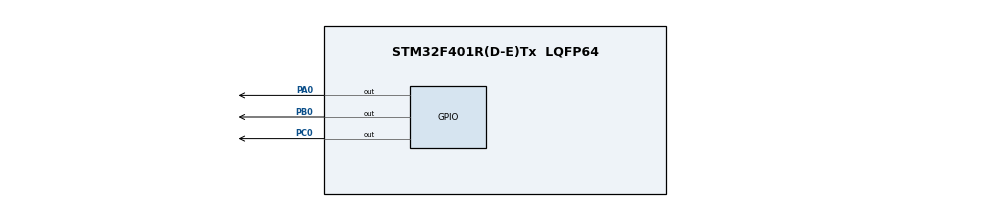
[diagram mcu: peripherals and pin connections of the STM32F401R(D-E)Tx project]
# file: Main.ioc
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Mcu.Family=STM32F4
Mcu.Name=STM32F401R(D-E)Tx
Mcu.Package=LQFP64
NVIC.PriorityGroup=NVIC_PRIORITYGROUP_4
PA0-WKUP.Signal=GPIO_Output
PA13.Mode=JTAG_4_pins
PA13.Signal=SYS_JTMS-SWDIO
PA14.Mode=JTAG_4_pins
PA14.Signal=SYS_JTCK-SWCLK
PA15.Mode=JTAG_4_pins
PA15.Signal=SYS_JTDI
PB0.Signal=GPIO_Output
PB3.Mode=JTAG_4_pins
PB3.Signal=SYS_JTDO-SWO
PC0.Signal=GPIO_Output
ProjectManager.HeapSize=0x200
ProjectManager.StackSize=0x400
ProjectManager.TargetToolchain=MDK-ARM V5.32
RCC.AHBFreq_Value=16000000
RCC.APB1Freq_Value=16000000
RCC.APB2Freq_Value=16000000
RCC.CortexFreq_Value=16000000
RCC.HSE_VALUE=25000000
RCC.HSI_VALUE=16000000
RCC.LSE_VALUE=32768
RCC.SYSCLKFreq_VALUE=16000000
RCC.VCOOutputFreq_Value=192000000
board=custom

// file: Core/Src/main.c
/* USER CODE BEGIN Header */
/**
  ******************************************************************************
  * @file           : main.c
  * @brief          : Main program body
  ******************************************************************************
  * @attention
  *
  * Copyright (c) 2026 STMicroelectronics.
  * All rights reserved.
  *
  * This software is licensed under terms that can be found in the LICENSE file
  * in the root directory of this software component.
  * If no LICENSE file comes with this software, it is provided AS-IS.
  *
  ******************************************************************************
  */
/* USER CODE END Header */
#include "main.h"

void SystemClock_Config(void);
static void MX_GPIO_Init(void);

int main(void)
{

  /* MCU Configuration--------------------------------------------------------*/

  /* Reset of all peripherals, Initializes the Flash interface and the Systick. */
  LL_APB2_GRP1_EnableClock(LL_APB2_GRP1_PERIPH_SYSCFG);
  LL_APB1_GRP1_EnableClock(LL_APB1_GRP1_PERIPH_PWR);

  /* System interrupt init*/
  NVIC_SetPriorityGrouping(NVIC_PRIORITYGROUP_4);

  /* SysTick_IRQn interrupt configuration */
  NVIC_SetPriority(SysTick_IRQn, NVIC_EncodePriority(NVIC_GetPriorityGrouping(),15, 0));

  /* Configure the system clock */
  SystemClock_Config();

  /* Initialize all configured peripherals */
  MX_GPIO_Init();

  /* Infinite loop */
  /* USER CODE BEGIN WHILE */
	LL_AHB1_GRP1_DisableClock(LL_AHB1_GRP1_PERIPH_GPIOA);
	LL_AHB1_GRP1_DisableClock(LL_AHB1_GRP1_PERIPH_GPIOB);
	LL_AHB1_GRP1_DisableClock(LL_AHB1_GRP1_PERIPH_GPIOC);

	LL_AHB1_GRP1_EnableClock(LL_AHB1_GRP1_PERIPH_GPIOA);
	LL_AHB1_GRP1_EnableClock(LL_AHB1_GRP1_PERIPH_GPIOB);
  LL_AHB1_GRP1_EnableClock(LL_AHB1_GRP1_PERIPH_GPIOC);

	LL_GPIO_SetOutputPin(GPIOA, LL_GPIO_PIN_0);
	LL_GPIO_SetOutputPin(GPIOB, LL_GPIO_PIN_0);
	LL_GPIO_SetOutputPin(GPIOC, LL_GPIO_PIN_0);

  while (1){
    /* USER CODE END WHILE */

    /* USER CODE BEGIN 3 */
//		LL_GPIO_TogglePin(GPIOA, LL_GPIO_PIN_0);
//		LL_GPIO_TogglePin(GPIOB, LL_GPIO_PIN_0);
//		LL_GPIO_TogglePin(GPIOC, LL_GPIO_PIN_0);
//		LL_mDelay(500);
  }
  /* USER CODE END 3 */
}

void SystemClock_Config(void)
{
  LL_FLASH_SetLatency(LL_FLASH_LATENCY_0);
  while(LL_FLASH_GetLatency()!= LL_FLASH_LATENCY_0)
  {
  }
  LL_PWR_SetRegulVoltageScaling(LL_PWR_REGU_VOLTAGE_SCALE2);
  LL_RCC_HSI_SetCalibTrimming(16);
  LL_RCC_HSI_Enable();

   /* Wait till HSI is ready */
  while(LL_RCC_HSI_IsReady() != 1)
  {

  }
  LL_RCC_SetAHBPrescaler(LL_RCC_SYSCLK_DIV_1);
  LL_RCC_SetAPB1Prescaler(LL_RCC_APB1_DIV_1);
  LL_RCC_SetAPB2Prescaler(LL_RCC_APB2_DIV_1);
  LL_RCC_SetSysClkSource(LL_RCC_SYS_CLKSOURCE_HSI);

   /* Wait till System clock is ready */
  while(LL_RCC_GetSysClkSource() != LL_RCC_SYS_CLKSOURCE_STATUS_HSI)
  {

  }
  LL_Init1msTick(16000000);
  LL_SetSystemCoreClock(16000000);
  LL_RCC_SetTIMPrescaler(LL_RCC_TIM_PRESCALER_TWICE);
}

static void MX_GPIO_Init(void)
{
  LL_GPIO_InitTypeDef GPIO_InitStruct = {0};

  /* GPIO Ports Clock Enable */
  LL_AHB1_GRP1_EnableClock(LL_AHB1_GRP1_PERIPH_GPIOC);
  LL_AHB1_GRP1_EnableClock(LL_AHB1_GRP1_PERIPH_GPIOA);
  LL_AHB1_GRP1_EnableClock(LL_AHB1_GRP1_PERIPH_GPIOB);

  /**/
  LL_GPIO_ResetOutputPin(GPIOC, LL_GPIO_PIN_0);

  /**/
  LL_GPIO_ResetOutputPin(GPIOA, LL_GPIO_PIN_0);

  /**/
  LL_GPIO_ResetOutputPin(GPIOB, LL_GPIO_PIN_0);

  /**/
  GPIO_InitStruct.Pin = LL_GPIO_PIN_0;
  GPIO_InitStruct.Mode = LL_GPIO_MODE_OUTPUT;
  GPIO_InitStruct.Speed = LL_GPIO_SPEED_FREQ_LOW;
  GPIO_InitStruct.OutputType = LL_GPIO_OUTPUT_PUSHPULL;
  GPIO_InitStruct.Pull = LL_GPIO_PULL_NO;
  LL_GPIO_Init(GPIOC, &GPIO_InitStruct);

  /**/
  GPIO_InitStruct.Pin = LL_GPIO_PIN_0;
  GPIO_InitStruct.Mode = LL_GPIO_MODE_OUTPUT;
  GPIO_InitStruct.Speed = LL_GPIO_SPEED_FREQ_LOW;
  GPIO_InitStruct.OutputType = LL_GPIO_OUTPUT_PUSHPULL;
  GPIO_InitStruct.Pull = LL_GPIO_PULL_NO;
  LL_GPIO_Init(GPIOA, &GPIO_InitStruct);

  /**/
  GPIO_InitStruct.Pin = LL_GPIO_PIN_0;
  GPIO_InitStruct.Mode = LL_GPIO_MODE_OUTPUT;
  GPIO_InitStruct.Speed = LL_GPIO_SPEED_FREQ_LOW;
  GPIO_InitStruct.OutputType = LL_GPIO_OUTPUT_PUSHPULL;
  GPIO_InitStruct.Pull = LL_GPIO_PULL_NO;
  LL_GPIO_Init(GPIOB, &GPIO_InitStruct);

}

void Error_Handler(void)
{
  __disable_irq();
  while (1)
  {
  }
}
